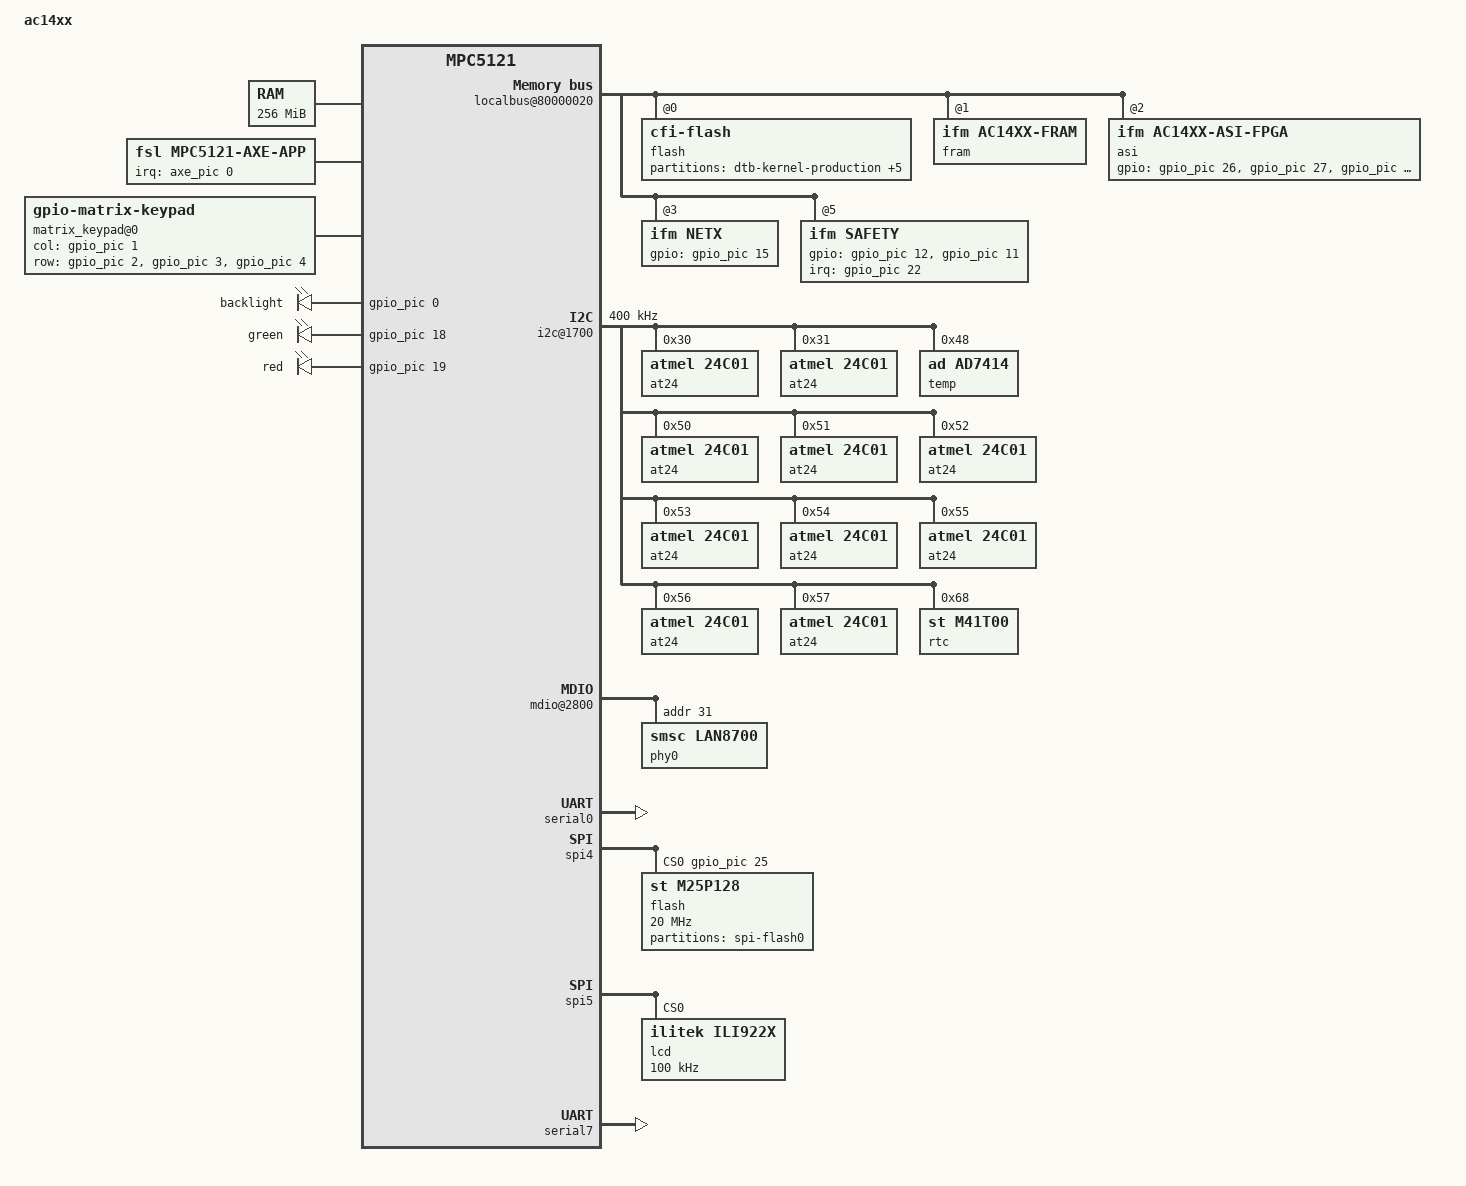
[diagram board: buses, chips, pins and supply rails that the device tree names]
#include "mpc5121.dtsi"
/ {
	model = "ac14xx";
	compatible = "ifm,ac14xx", "fsl,mpc5121";
	#address-cells = <1>;
	#size-cells = <1>;
	aliases {
		serial0 = &serial0;
		serial1 = &serial7;
		spi4 = &spi4;
		spi5 = &spi5;
	};
	cpus {
		PowerPC,5121@0 {
			timebase-frequency = <40000000>;	 
			bus-frequency = <160000000>;		 
			clock-frequency = <400000000>;		 
		};
	};
	memory {
		reg = <0x00000000 0x10000000>;			 
	};
	nfc@40000000 {
		status = "disabled";
	};
	localbus@80000020 {
		ranges = <0x0 0x0 0xfc000000 0x04000000	 
			  0x1 0x0 0xe0000000 0x00010000  
			  0x2 0x0 0xe0100000 0x00080000  
			  0x3 0x0 0xe0300000 0x00020000  
			  0x5 0x0 0xe0400000 0x00010000  
			  0x6 0x0 0xe0200000 0x00080000>;  
		flash@0,0 {
			compatible = "cfi-flash";
			reg = <0 0x00000000 0x04000000>;
			#address-cells = <1>;
			#size-cells = <1>;
			bank-width = <2>;
			device-width = <2>;
			partition@0 {
				label = "dtb-kernel-production";
				reg = <0x00000000 0x00400000>;
			};
			partition@1 {
				label = "filesystem-production";
				reg = <0x00400000 0x03400000>;
			};
			partition@2 {
				label = "recovery";
				reg = <0x03800000 0x00700000>;
			};
			partition@3 {
				label = "uboot-code";
				reg = <0x03f00000 0x00040000>;
			};
			partition@4 {
				label = "uboot-env1";
				reg = <0x03f40000 0x00020000>;
			};
			partition@5 {
				label = "uboot-env2";
				reg = <0x03f60000 0x00020000>;
			};
		};
		fram@1,0 {
			compatible = "ifm,ac14xx-fram", "linux,uio-pdrv-genirq";
			reg = <1 0x00000000 0x00010000>;
		};
		asi@2,0 {
			reg = <2 0x00000000 0x00080000
			       6 0x00000000 0x00080000>;
			#address-cells = <1>;
			#size-cells = <1>;
			compatible = "ifm,ac14xx-asi-fpga";
			gpios = <
				&gpio_pic 26 0	 
				&gpio_pic 27 0	 
				&gpio_pic 10 0	 
				>;
			master@1 {
				interrupts = <20 0x2>;
				interrupt-parent = <&gpio_pic>;
				chipselect = <2 0x00009000 0x00009100>;
				label = "AS-i master 1";
			};
			master@2 {
				interrupts = <21 0x2>;
				interrupt-parent = <&gpio_pic>;
				chipselect = <6 0x00009000 0x00009100>;
				label = "AS-i master 2";
			};
		};
		netx@3,0 {
			compatible = "ifm,netx";
			reg = <0x3 0x00000000 0x00020000>;
			chipselect = <3 0x00101140 0x00203100>;
			interrupts = <17 0x8>;
			gpios = <&gpio_pic 15 0>;
		};
		safety@5,0 {
			compatible = "ifm,safety";
			reg = <0x5 0x00000000 0x00010000>;
			chipselect = <5 0x00009000 0x00009100>;
			interrupts = <22 0x2>;
			interrupt-parent = <&gpio_pic>;
			gpios = <
				&gpio_pic 12 0	 
				&gpio_pic 11 0	 
				>;
		};
	};
	clocks {
		osc {
			clock-frequency = <25000000>;
		};
	};
	soc@80000000 {
		bus-frequency = <80000000>;	 
		clock@f00 {
			compatible = "fsl,mpc5121rev2-clock", "fsl,mpc5121-clock";
		};
		gpio_pic: gpio@1100 {
			gpio-controller;
			#gpio-cells = <2>;
			interrupt-controller;
			#interrupt-cells = <2>;
		};
		sdhc@1500 {
			cd-gpios = <&gpio_pic 23 0>;	 
			wp-gpios = <&gpio_pic 24 0>;	 
			wp-inverted;			 
		};
		i2c@1700 {
			clock-frequency = <400000>;
			at24@30 {
				compatible = "atmel,24c01";
				reg = <0x30>;
			};
			at24@31 {
				compatible = "atmel,24c01";
				reg = <0x31>;
			};
			temp@48 {
				compatible = "ad,ad7414";
				reg = <0x48>;
			};
			at24@50 {
				compatible = "atmel,24c01";
				reg = <0x50>;
			};
			at24@51 {
				compatible = "atmel,24c01";
				reg = <0x51>;
			};
			at24@52 {
				compatible = "atmel,24c01";
				reg = <0x52>;
			};
			at24@53 {
				compatible = "atmel,24c01";
				reg = <0x53>;
			};
			at24@54 {
				compatible = "atmel,24c01";
				reg = <0x54>;
			};
			at24@55 {
				compatible = "atmel,24c01";
				reg = <0x55>;
			};
			at24@56 {
				compatible = "atmel,24c01";
				reg = <0x56>;
			};
			at24@57 {
				compatible = "atmel,24c01";
				reg = <0x57>;
			};
			rtc@68 {
				compatible = "st,m41t00";
				reg = <0x68>;
			};
		};
		axe_pic: axe-base@2000 {
			compatible = "fsl,mpc5121-axe-base";
			reg = <0x2000 0x100>;
			interrupts = <42 0x8>;
			interrupt-controller;
			#interrupt-cells = <2>;
		};
		axe-app {
			compatible = "fsl,mpc5121-axe-app";
			interrupt-parent = <&axe_pic>;
			interrupts = <
					0 0x0	1 0x0	2 0x0	3 0x0
					4 0x0	5 0x0	6 0x0	7 0x0
					8 0x0	9 0x0	10 0x0	11 0x0
				>;
		};
		display@2100 {
			edid = [00 FF FF FF FF FF FF 00 14 94 00 00 00 00 00 00
				0A 12 01 03 80 1C 23 78 CA 88 FF 94 52 54 8E 27
				1E 4C 50 00 00 00 01 01 01 01 01 01 01 01 01 01
				01 01 01 01 01 01 FB 00 B0 14 00 DC 05 00 08 04
				21 00 1C 23 00 00 00 18 00 00 00 FD 00 38 3C 1F
				3C 01 0A 20 20 20 20 20 20 20 00 00 00 FC 00 45
				54 30 31 38 30 30 33 44 4D 55 0A 0A 00 00 00 10
				00 41 30 30 30 30 30 30 30 30 30 30 30 31 00 D5];
		};
		can@2300 {
			status = "disabled";
		};
		can@2380 {
			status = "disabled";
		};
		viu@2400 {
			status = "disabled";
		};
		mdio@2800 {
			phy0: ethernet-phy@1f {
				compatible = "smsc,lan8700";
				reg = <0x1f>;
			};
		};
		enet: ethernet@2800 {
			phy-handle = <&phy0>;
		};
		usb@3000 {
			status = "disabled";
		};
		usb@4000 {
			status = "disabled";
		};
		serial0: psc@11300 {
			compatible = "fsl,mpc5121-psc-uart", "fsl,mpc5121-psc";
			fsl,rx-fifo-size = <512>;
			fsl,tx-fifo-size = <512>;
		};
		spi4: psc@11400 {
			compatible = "fsl,mpc5121-psc-spi", "fsl,mpc5121-psc";
			fsl,rx-fifo-size = <768>;
			fsl,tx-fifo-size = <768>;
			#address-cells = <1>;
			#size-cells = <0>;
			num-cs = <1>;
			cs-gpios = <&gpio_pic 25 0>;
			flash: m25p128@0 {
				compatible = "st,m25p128";
				spi-max-frequency = <20000000>;
				reg = <0>;
				#address-cells = <1>;
				#size-cells = <1>;
				partition@0 {
					label = "spi-flash0";
					reg = <0x00000000 0x01000000>;
				};
			};
		};
		spi5: psc@11500 {
			compatible = "fsl,mpc5121-psc-spi", "fsl,mpc5121-psc";
			fsl,mode = "spi-master";
			fsl,rx-fifo-size = <128>;
			fsl,tx-fifo-size = <128>;
			#address-cells = <1>;
			#size-cells = <0>;
			lcd@0 {
				compatible = "ilitek,ili922x";
				reg = <0>;
				spi-max-frequency = <100000>;
				spi-cpol;
				spi-cpha;
			};
		};
		serial7: psc@11700 {
			compatible = "fsl,mpc5121-psc-uart", "fsl,mpc5121-psc";
			fsl,rx-fifo-size = <512>;
			fsl,tx-fifo-size = <512>;
		};
		matrix_keypad@0 {
			compatible = "gpio-matrix-keypad";
			debounce-delay-ms = <5>;
			col-scan-delay-us = <1>;
			gpio-activelow;
			col-gpios-binary;
			col-switch-delay-ms = <200>;
			col-gpios = <&gpio_pic 1 0>;	 
			row-gpios = <&gpio_pic 2 0	 
				     &gpio_pic 3 0	 
				     &gpio_pic 4 0>;	 
			linux,keymap = <0x0000006e	 
					0x01000067	 
					0x02000066	 
					0x00010069	 
					0x0101006a	 
					0x0201006c>;	 
		};
	};
	leds {
		compatible = "gpio-leds";
		backlight {
			label = "backlight";
			gpios = <&gpio_pic 0 0>;
			default-state = "keep";
		};
		green {
			label = "green";
			gpios = <&gpio_pic 18 0>;
			default-state = "keep";
		};
		red {
			label = "red";
			gpios = <&gpio_pic 19 0>;
			default-state = "keep";
		};
	};
};
